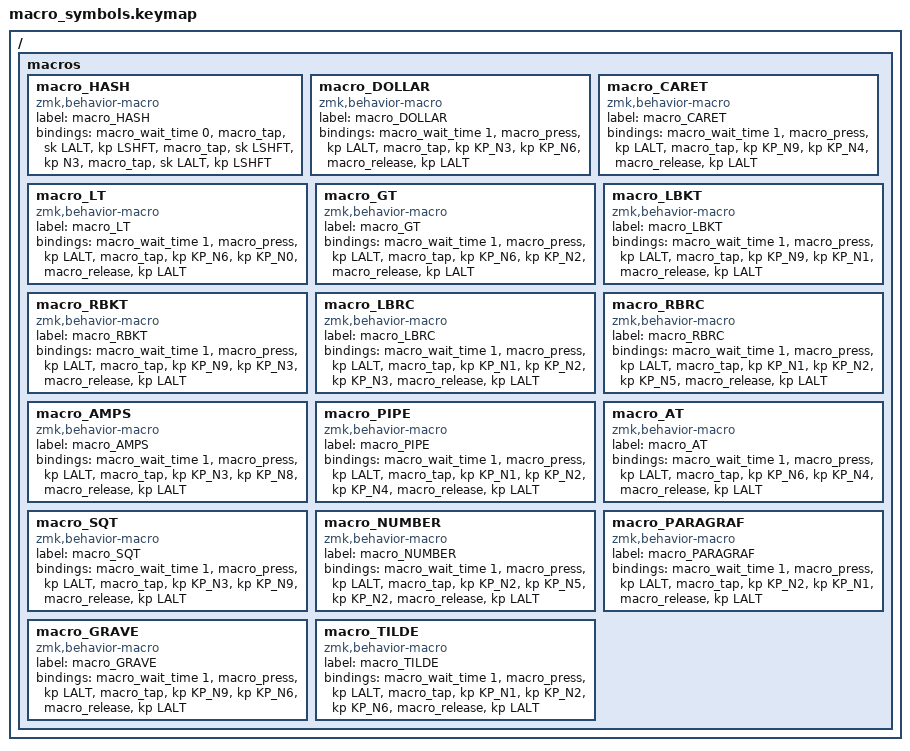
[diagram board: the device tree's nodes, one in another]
/ {
    macros {
        macro_HASH: macro_HASH {
            label = "macro_HASH";
            compatible = "zmk,behavior-macro";
            #binding-cells = <0>;
            bindings
                = <&macro_wait_time 0>
                , <&macro_tap &sk LALT &kp LSHFT>
                , <&macro_tap &sk LSHFT &kp N3>
                , <&macro_tap &sk LALT &kp LSHFT>
                ;
        };
        macro_DOLLAR: macro_DOLLAR {
            label = "macro_DOLLAR";
            compatible = "zmk,behavior-macro";
            #binding-cells = <0>;
            bindings
                = <&macro_wait_time 1>
                , <&macro_press &kp LALT>
                , <&macro_tap &kp KP_N3 &kp KP_N6>
                , <&macro_release &kp LALT>
                ;
        };
        macro_CARET: macro_CARET {
            label = "macro_CARET";
            compatible = "zmk,behavior-macro";
            #binding-cells = <0>;
            bindings
                = <&macro_wait_time 1>
                , <&macro_press &kp LALT>
                , <&macro_tap &kp KP_N9 &kp KP_N4>
                , <&macro_release &kp LALT>
                ;
        };
        macro_LT: macro_LT {
            label = "macro_LT";
            compatible = "zmk,behavior-macro";
            #binding-cells = <0>;
            bindings
                = <&macro_wait_time 1>
                , <&macro_press &kp LALT>
                , <&macro_tap &kp KP_N6 &kp KP_N0>
                , <&macro_release &kp LALT>
                ;
        };
        macro_GT: macro_GT {
            label = "macro_GT";
            compatible = "zmk,behavior-macro";
            #binding-cells = <0>;
            bindings
                = <&macro_wait_time 1>
                , <&macro_press &kp LALT>
                , <&macro_tap &kp KP_N6 &kp KP_N2>
                , <&macro_release &kp LALT>
                ;
        };
        macro_LBKT: macro_LBKT {
            label = "macro_LBKT";
            compatible = "zmk,behavior-macro";
            #binding-cells = <0>;
            bindings
                = <&macro_wait_time 1>
                , <&macro_press &kp LALT>
                , <&macro_tap &kp KP_N9 &kp KP_N1>
                , <&macro_release &kp LALT>
                ;
        };
        macro_RBKT: macro_RBKT {
            label = "macro_RBKT";
            compatible = "zmk,behavior-macro";
            #binding-cells = <0>;
            bindings
                = <&macro_wait_time 1>
                , <&macro_press &kp LALT>
                , <&macro_tap &kp KP_N9 &kp KP_N3>
                , <&macro_release &kp LALT>
                ;
        };
        macro_LBRC: macro_LBRC {
            label = "macro_LBRC";
            compatible = "zmk,behavior-macro";
            #binding-cells = <0>;
            bindings
                = <&macro_wait_time 1>
                , <&macro_press &kp LALT>
                , <&macro_tap &kp KP_N1 &kp KP_N2 &kp KP_N3>
                , <&macro_release &kp LALT>
                ;
        };
        macro_RBRC: macro_RBRC {
            label = "macro_RBRC";
            compatible = "zmk,behavior-macro";
            #binding-cells = <0>;
            bindings
                = <&macro_wait_time 1>
                , <&macro_press &kp LALT>
                , <&macro_tap &kp KP_N1 &kp KP_N2 &kp KP_N5>
                , <&macro_release &kp LALT>
                ;
        };
        macro_AMPS: macro_AMPS {
            label = "macro_AMPS";
            compatible = "zmk,behavior-macro";
            #binding-cells = <0>;
            bindings
                = <&macro_wait_time 1>
                , <&macro_press &kp LALT>
                , <&macro_tap &kp KP_N3 &kp KP_N8>
                , <&macro_release &kp LALT>
                ;
        };
        macro_PIPE: macro_PIPE {
            label = "macro_PIPE";
            compatible = "zmk,behavior-macro";
            #binding-cells = <0>;
            bindings
                = <&macro_wait_time 1>
                , <&macro_press &kp LALT>
                , <&macro_tap &kp KP_N1 &kp KP_N2 &kp KP_N4>
                , <&macro_release &kp LALT>
                ;
        };
        macro_AT: macro_AT {
            label = "macro_AT";
            compatible = "zmk,behavior-macro";
            #binding-cells = <0>;
            bindings
                = <&macro_wait_time 1>
                , <&macro_press &kp LALT>
                , <&macro_tap &kp KP_N6 &kp KP_N4>
                , <&macro_release &kp LALT>
                ;
        };
        macro_SQT: macro_SQT {
            label = "macro_SQT";
            compatible = "zmk,behavior-macro";
            #binding-cells = <0>;
            bindings
                = <&macro_wait_time 1>
                , <&macro_press &kp LALT>
                , <&macro_tap &kp KP_N3 &kp KP_N9>
                , <&macro_release &kp LALT>
                ;
        };
        macro_NUMBER: macro_NUMBER {
            label = "macro_NUMBER";
            compatible = "zmk,behavior-macro";
            #binding-cells = <0>;
            bindings
                = <&macro_wait_time 1>
                , <&macro_press &kp LALT>
                , <&macro_tap &kp KP_N2 &kp KP_N5 &kp KP_N2>
                , <&macro_release &kp LALT>
                ;
        };
        macro_PARAGRAF: macro_PARAGRAF {
            label = "macro_PARAGRAF";
            compatible = "zmk,behavior-macro";
            #binding-cells = <0>;
            bindings
                = <&macro_wait_time 1>
                , <&macro_press &kp LALT>
                , <&macro_tap &kp KP_N2 &kp KP_N1>
                , <&macro_release &kp LALT>
                ;
        };
        macro_GRAVE: macro_GRAVE {
            label = "macro_GRAVE";
            compatible = "zmk,behavior-macro";
            #binding-cells = <0>;
            bindings
                = <&macro_wait_time 1>
                , <&macro_press &kp LALT>
                , <&macro_tap &kp KP_N9 &kp KP_N6>
                , <&macro_release &kp LALT>
                ;
        };
        macro_TILDE: macro_TILDE {
            label = "macro_TILDE";
            compatible = "zmk,behavior-macro";
            #binding-cells = <0>;
            bindings
                = <&macro_wait_time 1>
                , <&macro_press &kp LALT>
                , <&macro_tap &kp KP_N1 &kp KP_N2 &kp KP_N6>
                , <&macro_release &kp LALT>
                ;
        };
   };
};
